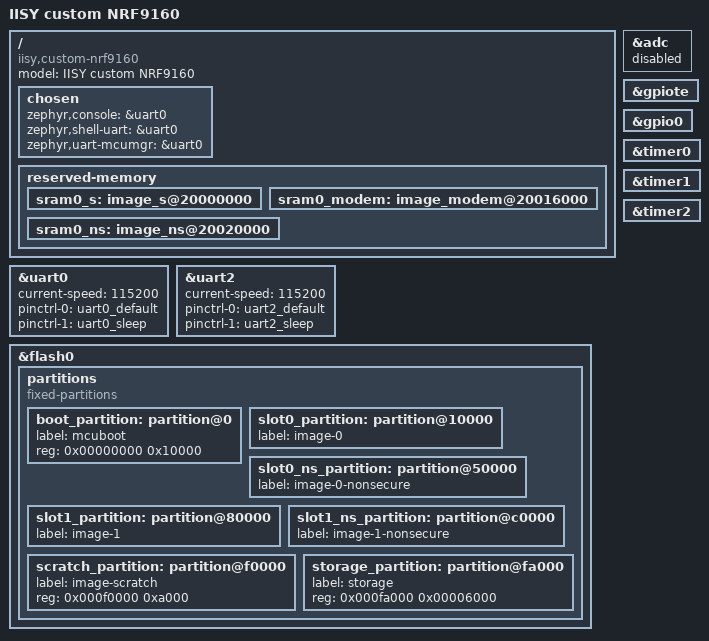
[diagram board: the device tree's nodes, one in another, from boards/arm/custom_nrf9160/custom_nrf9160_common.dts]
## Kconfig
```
#
# Copyright (c) 2019 Nordic Semiconductor
#
# SPDX-License-Identifier: LicenseRef-Nordic-5-Clause
#

source "Kconfig.zephyr"

menu "Nordic Serial LTE Modem"

config SLM_CUSTOMIZED
	bool "Flag for customized functionality"
	help
	  Enable this flag to include customized logic.

config SLM_AT_MODE
	bool "Serial LTE Modem by raw AT mode"
	default y
	select AT_CMD_PARSER

config SLM_AT_MAX_PARAM
	int "Maximum number of parameters in AT command"
	default 42

config SLM_NATIVE_TLS
	bool "Use Zephyr mbedTLS"

#
# external XTAL for UART
#
config SLM_EXTERNAL_XTAL
	bool "Use external XTAL for UARTE"
	default y

#
# Inter-Connect
#
config SLM_UART_HWFC_RUNTIME
	bool "Support of UART HWFC runtime configuration"
	help
		Selected if hw-flow-control is enabled in devicetree
choice
	prompt "UART for interconnect"
	help
		Selects which UART to use for interconnect:
		-  UART 0
		-  UART 2
	config SLM_CONNECT_UART_0
		bool "UART 0"
		select SLM_UART_HWFC_RUNTIME if $(dt_node_has_prop,uart0,hw-flow-control)

	config SLM_CONNECT_UART_2
		bool "UART 2"
		select SLM_UART_HWFC_RUNTIME if $(dt_node_has_prop,uart2,hw-flow-control)
endchoice

choice
	prompt "Termination mode"
	default SLM_CR_LF_TERMINATION
	help
		Sets the command terminator used by the serial terminal.
		Available options are:
		-  CR termination
		-  LF termination
		-  CR+LF termination
	config SLM_CR_TERMINATION
		bool "CR termination"
	config SLM_LF_TERMINATION
		bool "LF termination"
	config SLM_CR_LF_TERMINATION
		bool "CR+LF termination"
endchoice

#
# GPIO wakeup
#
config SLM_START_SLEEP
	bool "Enter sleep on startup"
	help
	  Put nRF9160 into deep sleep mode after startup.

config SLM_WAKEUP_PIN
	int "Wakeup pin"
	default -1
	help
	  Interface GPIO to wake up from sleep or exit idle

config SLM_INDICATE_PIN
	int "Indicate pin"
	default -1
	help
	  Interface GPIO pin used to indicate that data is available or an unexpected reset has occurred

config SLM_INDICATE_TIME
	int "Indication period"
	default 100
	help
	  GPIO active indication time in milliseconds. This setting specify the period length for the pin to be active

#
# Socket
#
config SLM_SOCKET_RX_MAX
	int "Maximum RX buffer size for receiving socket data"
	range 576 708
	default 576
	help
	  Default: NET_IPV4_MTU (576)
	  Maximum: MSS setting in modem (708)

#
# TCP/TLS proxy
#
config SLM_TCP_POLL_TIME
	int "Poll time-out in seconds for TCP connection"
	default 10

config SLM_UDP_POLL_TIME
	int "Poll time-out in seconds for UDP connection"
	default 10

#
# Data mode
#
config SLM_DATAMODE_TERMINATOR
	string "Pattern string to terminate data mode"
	default "+++"
	help
	  Use a pattern to terminate data mode

#
# Configurable services
#
config SLM_SMS
	bool "SMS support in SLM"
	default n
	select SMS
	help
	  Support SMS send/receive in plain text

rsource "src/gnss/Kconfig"
rsource "src/ftp_c/Kconfig"
rsource "src/mqtt_c/Kconfig"
rsource "src/http_c/Kconfig"
rsource "src/twi/Kconfig"
rsource "src/gpio/Kconfig"
rsource "src/dfu/Kconfig"

module = SLM
module-str = serial modem
source "${ZEPHYR_BASE}/subsys/logging/Kconfig.template.log_config"

endmenu
```

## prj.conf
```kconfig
#
# Copyright (c) 2020 Nordic Semiconductor ASA
#
# SPDX-License-Identifier: LicenseRef-Nordic-5-Clause
#
# General config
CONFIG_LOG=y
CONFIG_LOG_DEFAULT_LEVEL=3
CONFIG_STACK_SENTINEL=y
CONFIG_NEWLIB_LIBC=y
CONFIG_NEWLIB_LIBC_FLOAT_PRINTF=y
CONFIG_RING_BUFFER=y

# Segger RTT
CONFIG_USE_SEGGER_RTT=y
CONFIG_RTT_CONSOLE=y
CONFIG_UART_CONSOLE=n
CONFIG_LOG_BACKEND_RTT=y
CONFIG_LOG_BACKEND_UART=n

# Network
CONFIG_NETWORKING=y
CONFIG_NET_SOCKETS=y
CONFIG_NET_NATIVE=n

# Modem library
CONFIG_NRF_MODEM_LIB=y
# Align the max FD entry to NRF_MODEM_MAX_SOCKET_COUNT(8)
CONFIG_POSIX_MAX_FDS=8
# Enable below for modem trace
#CONFIG_NRF_MODEM_LIB_TRACE_ENABLED=y
# Handle modem fault
CONFIG_NRF_MODEM_LIB_ON_FAULT_APPLICATION_SPECIFIC=y

# Use GPIO
CONFIG_GPIO=y
CONFIG_GPIO_NRFX=y

# UART interface
CONFIG_SERIAL=y
CONFIG_UART_ASYNC_API=y
CONFIG_NRFX_TIMER2=y

# Stacks and heaps
CONFIG_MAIN_STACK_SIZE=4096
CONFIG_HEAP_MEM_POOL_SIZE=16384
CONFIG_SYSTEM_WORKQUEUE_STACK_SIZE=4096

# Device power management
CONFIG_PM_DEVICE=y

# FOTA
CONFIG_HTTP_PARSER_URL=y
CONFIG_FOTA_DOWNLOAD=y
CONFIG_FOTA_DOWNLOAD_PROGRESS_EVT=y
CONFIG_DFU_TARGET=y
CONFIG_DOWNLOAD_CLIENT=y
CONFIG_DOWNLOAD_CLIENT_STACK_SIZE=4096
CONFIG_BOOTLOADER_MCUBOOT=y
CONFIG_IMG_MANAGER=y

# FLASH
CONFIG_FLASH=y
CONFIG_FLASH_PAGE_LAYOUT=y
CONFIG_FLASH_MAP=y
CONFIG_MPU_ALLOW_FLASH_WRITE=y
CONFIG_IMG_ERASE_PROGRESSIVELY=y

# Settings
CONFIG_SETTINGS=y
CONFIG_SETTINGS_FCB=y
CONFIG_FCB=y

# nRF Cloud
CONFIG_NRF_CLOUD_MQTT=y
CONFIG_NRF_CLOUD_FOTA=n
CONFIG_NRF_CLOUD_AGPS=y
CONFIG_NRF_CLOUD_AGPS_FILTERED=n
CONFIG_NRF_CLOUD_PGPS=y
CONFIG_NRF_CLOUD_CELL_POS=y
CONFIG_NRF_CLOUD_LOG_LEVEL_INF=y
CONFIG_DATE_TIME=y
CONFIG_MODEM_INFO=y
CONFIG_MODEM_INFO_ADD_DATE_TIME=n
CONFIG_AT_MONITOR=y
CONFIG_MODEM_JWT=y
CONFIG_NRF_CLOUD_CLIENT_ID_SRC_INTERNAL_UUID=y

#
# SLM-specific configurations
#
CONFIG_SLM_CUSTOMIZED=n
CONFIG_SLM_LOG_LEVEL_INF=y
CONFIG_SLM_EXTERNAL_XTAL=n
CONFIG_SLM_START_SLEEP=n

# GNSS
CONFIG_SLM_GNSS=n

# nRF Cloud based location services
CONFIG_SLM_AGPS=n
CONFIG_SLM_PGPS=n
CONFIG_SLM_CELL_POS=n

# Serial DFU support
CONFIG_SLM_NRF52_DFU=n
CONFIG_SLM_NRF52_DFU_LEGACY=n

# FTP Client
CONFIG_SLM_FTPC=n

# MQTT Client
CONFIG_SLM_MQTTC=n

# nRF52 DFU
CONFIG_SLM_NRF52_DFU=n
CONFIG_SLM_NRF52_DFU_LEGACY=n
```

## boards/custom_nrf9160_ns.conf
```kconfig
#
# Copyright (c) 2021 Nordic Semiconductor ASA
#
# SPDX-License-Identifier: LicenseRef-Nordic-5-Clause
#

# Configuration file for custom NRF9160.
# This file is merged with prj.conf in the application folder, and options
# set here will take precedence if they are present in both files.

# Use UART_2
CONFIG_SLM_CONNECT_UART_2=y
CONFIG_UART_2_NRF_HW_ASYNC_TIMER=2
CONFIG_UART_2_NRF_HW_ASYNC=y
```

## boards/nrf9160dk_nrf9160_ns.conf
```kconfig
#
# Copyright (c) 2021 Nordic Semiconductor ASA
#
# SPDX-License-Identifier: LicenseRef-Nordic-5-Clause
#

# Configuration file for nRF9160DK.
# This file is merged with prj.conf in the application folder, and options
# set here will take precedence if they are present in both files.

# Use UART_0 (when working with PC terminal)
# unmask the following config
# CONFIG_SLM_CONNECT_UART_0=y
# CONFIG_UART_0_NRF_HW_ASYNC_TIMER=2
# CONFIG_UART_0_NRF_HW_ASYNC=y
# CONFIG_SLM_WAKEUP_PIN=6
# CONFIG_SLM_INDICATE_PIN=2

# Use UART_2 (when working with external MCU)
# unmask the following config
CONFIG_SLM_CONNECT_UART_2=y
CONFIG_UART_2_NRF_HW_ASYNC_TIMER=2
CONFIG_UART_2_NRF_HW_ASYNC=y
CONFIG_SLM_WAKEUP_PIN=31
CONFIG_SLM_INDICATE_PIN=30
```

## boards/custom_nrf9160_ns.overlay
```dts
/*
 * Copyright (c) 2021 Nordic Semiconductor ASA
 *
 * SPDX-License-Identifier: LicenseRef-Nordic-5-Clause
 */

&uart2 {
	compatible = "nordic,nrf-uarte";
	current-speed = <115200>;
	status = "okay";

	pinctrl-0 = <&uart2_default_alt>;
	pinctrl-1 = <&uart2_sleep_alt>;
	pinctrl-names = "default", "sleep";
};

&pinctrl {
	uart2_default_alt: uart2_default_alt {
		group1 {
			psels = <NRF_PSEL(UART_TX, 0, 29)>,
				<NRF_PSEL(UART_RX, 0, 28)>;
		};
	};

	uart2_sleep_alt: uart2_sleep_alt {
		group1 {
			psels = <NRF_PSEL(UART_TX, 0, 29)>,
				<NRF_PSEL(UART_RX, 0, 28)>;
			low-power-enable;
		};
	};
};
```

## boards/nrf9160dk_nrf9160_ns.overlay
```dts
/*
 * Copyright (c) 2021 Nordic Semiconductor ASA
 *
 * SPDX-License-Identifier: LicenseRef-Nordic-5-Clause
 */

&uart2 {
	compatible = "nordic,nrf-uarte";
	current-speed = <115200>;
	status = "okay";

	pinctrl-0 = <&uart2_default_alt>;
	pinctrl-1 = <&uart2_sleep_alt>;
	pinctrl-names = "default", "sleep";
};

&i2c2 {
	status = "disabled";
};

&pinctrl {
	uart2_default_alt: uart2_default_alt {
		group1 {
			psels = <NRF_PSEL(UART_TX, 0, 11)>,
				<NRF_PSEL(UART_RX, 0, 12)>;
		};
	};

	uart2_sleep_alt: uart2_sleep_alt {
		group1 {
			psels = <NRF_PSEL(UART_TX, 0, 11)>,
				<NRF_PSEL(UART_RX, 0, 12)>;
			low-power-enable;
		};
	};
};
```

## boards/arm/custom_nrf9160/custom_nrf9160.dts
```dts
/*
 * Copyright (c) 2018-2020 Nordic Semiconductor ASA
 *
 * SPDX-License-Identifier: Apache-2.0
 */

/dts-v1/;
#include <nordic/nrf9160_sica.dtsi>
#include "custom_nrf9160_common.dts"

/ {
	chosen {
		zephyr,sram = &sram0_s;
		zephyr,flash = &flash0;
		zephyr,code-partition = &slot0_partition;
		zephyr,sram-secure-partition = &sram0_s;
		zephyr,sram-non-secure-partition = &sram0_ns;
	};
};
```

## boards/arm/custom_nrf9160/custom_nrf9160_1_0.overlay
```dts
/*
 * Copyright (c) 2021 Nordic Semiconductor ASA
 *
 * SPDX-License-Identifier: Apache-2.0
 */

#include "custom_nrf9160_common_1_0.dtsi"
```

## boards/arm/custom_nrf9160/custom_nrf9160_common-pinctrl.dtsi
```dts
/*
 * Copyright (c) 2022 Nordic Semiconductor
 * SPDX-License-Identifier: Apache-2.0
 */

&pinctrl {
	uart0_default: uart0_default {
		group1 {
			psels = <NRF_PSEL(UART_TX, 0, 22)>,
				<NRF_PSEL(UART_RX, 0, 21)>;
		};
	};

	uart0_sleep: uart0_sleep {
		group1 {
			psels = <NRF_PSEL(UART_TX, 0, 22)>,
				<NRF_PSEL(UART_RX, 0, 21)>;
			low-power-enable;
		};
	};

	uart2_default: uart2_default {
		group1 {
			psels = <NRF_PSEL(UART_TX, 0, 29)>,
				<NRF_PSEL(UART_RX, 0, 28)>;
		};
	};

	uart2_sleep: uart2_sleep {
		group1 {
			psels = <NRF_PSEL(UART_TX, 0, 29)>,
				<NRF_PSEL(UART_RX, 0, 28)>;
			low-power-enable;
		};
	};
};
```

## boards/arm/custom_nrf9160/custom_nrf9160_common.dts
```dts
/*
 * Copyright (c) 2018-2020 Nordic Semiconductor ASA
 *
 * SPDX-License-Identifier: Apache-2.0
 */
#include "custom_nrf9160_common-pinctrl.dtsi"

/ {
	model = "IISY custom NRF9160";
	compatible = "iisy,custom-nrf9160";

	chosen {
		zephyr,console = &uart0;
		zephyr,shell-uart = &uart0;
		zephyr,uart-mcumgr = &uart0;
	};
};

&adc {
	status = "disabled";
};

&gpiote {
	status = "okay";
};

&gpio0 {
	status = "okay";
};

&uart0 {
	status = "okay";
	current-speed = <115200>;
	pinctrl-0 = <&uart0_default>;
	pinctrl-1 = <&uart0_sleep>;
	pinctrl-names = "default", "sleep";
};

&uart2 {
	status = "okay";
	current-speed = <115200>;
	pinctrl-0 = <&uart2_default>;
	pinctrl-1 = <&uart2_sleep>;
	pinctrl-names = "default", "sleep";
};

&timer0 {
	status = "okay";
};

&timer1 {
	status = "okay";
};

&timer2 {
	status = "okay";
};

&flash0 {

	partitions {
		compatible = "fixed-partitions";
		#address-cells = <1>;
		#size-cells = <1>;

		boot_partition: partition@0 {
			label = "mcuboot";
			reg = <0x00000000 0x10000>;
		};
		slot0_partition: partition@10000 {
			label = "image-0";
		};
		slot0_ns_partition: partition@50000 {
			label = "image-0-nonsecure";
		};
		slot1_partition: partition@80000 {
			label = "image-1";
		};
		slot1_ns_partition: partition@c0000 {
			label = "image-1-nonsecure";
		};
		scratch_partition: partition@f0000 {
			label = "image-scratch";
			reg = <0x000f0000 0xa000>;
		};
		storage_partition: partition@fa000 {
			label = "storage";
			reg = <0x000fa000 0x00006000>;
		};
	};
};

/ {

	reserved-memory {
		#address-cells = <1>;
		#size-cells = <1>;
		ranges;

		sram0_s: image_s@20000000 {
			/* Secure image memory */
		};

		sram0_modem: image_modem@20016000 {
			/* Modem (shared) memory */
		};

		sram0_ns: image_ns@20020000 {
			/* Non-Secure image memory */
		};
	};
};

/* Include partition configuration file */
#include "custom_nrf9160_partition_conf.dts"
```

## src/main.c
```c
/*
 * Copyright (c) 2019 Nordic Semiconductor ASA
 *
 * SPDX-License-Identifier: LicenseRef-Nordic-5-Clause
 */
#include <zephyr/logging/log.h>
#include <zephyr/logging/log_ctrl.h>

#include <zephyr/kernel.h>
#include <stdio.h>
#include <zephyr/drivers/uart.h>
#include <zephyr/drivers/gpio.h>
#include <string.h>
#include <nrf_modem.h>
#include <hal/nrf_gpio.h>
#include <hal/nrf_power.h>
#include <hal/nrf_regulators.h>
#include <modem/nrf_modem_lib.h>
#include <zephyr/dfu/mcuboot.h>
#include <dfu/dfu_target.h>
#include <zephyr/sys/reboot.h>
#include <zephyr/drivers/clock_control.h>
#include <zephyr/drivers/clock_control/nrf_clock_control.h>
#include "slm_at_host.h"
#include "slm_at_fota.h"

LOG_MODULE_REGISTER(slm, CONFIG_SLM_LOG_LEVEL);

#define SLM_WQ_STACK_SIZE	KB(4)
#define SLM_WQ_PRIORITY		K_LOWEST_APPLICATION_THREAD_PRIO
static K_THREAD_STACK_DEFINE(slm_wq_stack_area, SLM_WQ_STACK_SIZE);

static const struct device *gpio_dev;
static struct gpio_callback gpio_cb;
static struct k_work_delayable indicate_work;

/* global variable used across different files */
struct k_work_q slm_work_q;

/* global variable defined in different files */
extern uint8_t fota_type;
extern uint8_t fota_stage;
extern uint8_t fota_status;
extern int32_t fota_info;

/* global functions defined in different files */
int poweron_uart(void);
int slm_settings_init(void);
int slm_setting_fota_save(void);

/* Forward declarations */
static void indicate_wk(struct k_work *work);

#if defined(CONFIG_NRF_MODEM_LIB_ON_FAULT_APPLICATION_SPECIFIC)
static void on_modem_failure_shutdown(struct k_work *item);
static void on_modem_failure_reinit(struct k_work *item);

K_WORK_DELAYABLE_DEFINE(modem_failure_shutdown_work, on_modem_failure_shutdown);
K_WORK_DELAYABLE_DEFINE(modem_failure_reinit_work, on_modem_failure_reinit);

void nrf_modem_fault_handler(struct nrf_modem_fault_info *fault_info)
{
	char rsp[64];

	sprintf(rsp, "#XMODEM: FAULT,0x%x,0x%x", fault_info->reason, fault_info->program_counter);
	rsp_send(rsp, strlen(rsp));
	/* For now we wait 10 ms to give the trace handler time to process trace data. */
	k_work_reschedule(&modem_failure_shutdown_work, K_MSEC(10));
}

static void on_modem_failure_shutdown(struct k_work *work)
{
	char rsp[32];
	int ret = nrf_modem_lib_shutdown();

	ARG_UNUSED(work);
	sprintf(rsp, "#XMODEM: SHUTDOWN,%d", ret);
	rsp_send(rsp, strlen(rsp));
	k_work_reschedule(&modem_failure_reinit_work, K_MSEC(10));
}

static void on_modem_failure_reinit(struct k_work *work)
{
	char rsp[32];
	int ret = nrf_modem_lib_init(NORMAL_MODE);

	ARG_UNUSED(work);
	sprintf(rsp, "#XMODEM: INIT,%d", ret);
	rsp_send(rsp, strlen(rsp));
}
#endif /* CONFIG_NRF_MODEM_LIB_ON_FAULT_APPLICATION_SPECIFIC */

static int ext_xtal_control(bool xtal_on)
{
	int err = 0;
#if defined(CONFIG_SLM_EXTERNAL_XTAL)
	static struct onoff_manager *clk_mgr;

	if (xtal_on) {
		struct onoff_client cli = {};

		/* request external XTAL for UART */
		clk_mgr = z_nrf_clock_control_get_onoff(CLOCK_CONTROL_NRF_SUBSYS_HF);
		sys_notify_init_spinwait(&cli.notify);
		err = onoff_request(clk_mgr, &cli);
		if (err < 0) {
			LOG_ERR("Clock request failed: %d", err);
			return err;
		}
		while (sys_notify_fetch_result(&cli.notify, &err) < 0) {
			/*empty*/
		}
	} else {
		/* release external XTAL for UART */
		err = onoff_release(clk_mgr);
		if (err < 0) {
			LOG_ERR("Clock release failed: %d", err);
			return err;
		}
	}
#endif

	return err;
}

int indicate_start(void)
{
	int err = 0;

#if (CONFIG_SLM_INDICATE_PIN >= 0)
	if (k_work_delayable_is_pending(&indicate_work)) {
		return 0;
	}
	LOG_DBG("Start indicating");
	gpio_dev = device_get_binding(DT_LABEL(DT_NODELABEL(gpio0)));
	if (gpio_dev == NULL) {
		LOG_ERR("GPIO_0 bind error");
		return -EAGAIN;
	}
	err = gpio_pin_configure(gpio_dev, CONFIG_SLM_INDICATE_PIN, GPIO_OUTPUT);
	if (err) {
		LOG_ERR("GPIO_0 config error: %d", err);
		return -EAGAIN;
	}
	err = gpio_pin_set(gpio_dev, CONFIG_SLM_INDICATE_PIN, 1);
	if (err) {
		LOG_ERR("GPIO_0 set error: %d", err);
	} else {
		k_work_reschedule(&indicate_work, K_MSEC(CONFIG_SLM_INDICATE_TIME));
	}
#endif
	return err;
}

static void indicate_stop(void)
{
#if (CONFIG_SLM_INDICATE_PIN >= 0)
	if (gpio_pin_set(gpio_dev, CONFIG_SLM_INDICATE_PIN, 0) != 0) {
		LOG_WRN("GPIO_0 set error");
	}
	gpio_pin_configure(gpio_dev, CONFIG_SLM_INDICATE_PIN, GPIO_DISCONNECTED);
	LOG_DBG("Stop indicating");
#endif
}

static void gpio_cb_func(const struct device *dev, struct gpio_callback *gpio_cb, uint32_t pins)
{
#if (CONFIG_SLM_WAKEUP_PIN >= 0)
	int err;

	if ((BIT(CONFIG_SLM_WAKEUP_PIN) & pins) == 0) {
		return;
	}
	LOG_INF("Exit idle");
	if (k_work_delayable_is_pending(&indicate_work)) {
		(void)k_work_cancel_delayable(&indicate_work);
		indicate_stop();
	}

	err = ext_xtal_control(true);
	if (err < 0) {
		LOG_WRN("Failed to enable ext XTAL: %d", err);
	}
	err = poweron_uart();
	if (err) {
		LOG_ERR("Failed to power on uart: %d", err);
		return;
	}

	gpio_pin_interrupt_configure(gpio_dev, CONFIG_SLM_WAKEUP_PIN, GPIO_INT_DISABLE);
	gpio_remove_callback(gpio_dev, gpio_cb);
	gpio_pin_configure(gpio_dev, CONFIG_SLM_WAKEUP_PIN, GPIO_DISCONNECTED);
#endif
}

void enter_idle(void)
{
#if (CONFIG_SLM_WAKEUP_PIN >= 0)
	int err;

	gpio_dev = device_get_binding(DT_LABEL(DT_NODELABEL(gpio0)));
	if (gpio_dev == NULL) {
		LOG_ERR("GPIO_0 bind error");
		return;
	}
	err = gpio_pin_configure(gpio_dev, CONFIG_SLM_WAKEUP_PIN, GPIO_INPUT | GPIO_PULL_UP);
	if (err) {
		LOG_ERR("GPIO_0 config error: %d", err);
		return;
	}
	gpio_init_callback(&gpio_cb, gpio_cb_func, BIT(CONFIG_SLM_WAKEUP_PIN));
	err = gpio_add_callback(gpio_dev, &gpio_cb);
	if (err) {
		LOG_ERR("GPIO_0 add callback error: %d", err);
		return;
	}
	err = gpio_pin_interrupt_configure(gpio_dev, CONFIG_SLM_WAKEUP_PIN, GPIO_INT_LEVEL_LOW);
	if (err) {
		LOG_ERR("GPIO_0 enable callback error: %d", err);
		return;
	}

	err = ext_xtal_control(false);
	if (err < 0) {
		LOG_WRN("Failed to disable ext XTAL: %d", err);
	}
#endif
}

void enter_sleep(void)
{
#if (CONFIG_SLM_WAKEUP_PIN >= 0)
	/*
	 * Due to errata 4, Always configure PIN_CNF[n].INPUT before PIN_CNF[n].SENSE.
	 */
	nrf_gpio_cfg_input(CONFIG_SLM_WAKEUP_PIN, NRF_GPIO_PIN_PULLUP);
	nrf_gpio_cfg_sense_set(CONFIG_SLM_WAKEUP_PIN, NRF_GPIO_PIN_SENSE_LOW);

	k_sleep(K_MSEC(100));

	nrf_regulators_system_off(NRF_REGULATORS_NS);
#endif
}

static void handle_nrf_modem_lib_init_ret(void)
{
	int ret = nrf_modem_lib_get_init_ret();

	/* Handle return values relating to modem firmware update */
	switch (ret) {
	case 0:
		return; /* Initialization successful, no action required. */
	case MODEM_DFU_RESULT_OK:
		LOG_INF("MODEM UPDATE OK. Will run new firmware");
		fota_stage = FOTA_STAGE_COMPLETE;
		fota_status = FOTA_STATUS_OK;
		fota_info = 0;
		break;
	case MODEM_DFU_RESULT_UUID_ERROR:
	case MODEM_DFU_RESULT_AUTH_ERROR:
		LOG_ERR("MODEM UPDATE ERROR %d. Will run old firmware", ret);
		fota_status = FOTA_STATUS_ERROR;
		fota_info = ret;
		break;
	case MODEM_DFU_RESULT_HARDWARE_ERROR:
	case MODEM_DFU_RESULT_INTERNAL_ERROR:
		LOG_ERR("MODEM UPDATE FATAL ERROR %d. Modem failure", ret);
		fota_status = FOTA_STATUS_ERROR;
		fota_info = ret;
		break;
	default:
		/* All non-zero return codes other than DFU result codes are
		 * considered irrecoverable and a reboot is needed.
		 */
		LOG_ERR("nRF modem lib initialization failed, error: %d", ret);
		fota_status = FOTA_STATUS_ERROR;
		fota_info = ret;
		break;
	}

	slm_setting_fota_save();
	LOG_WRN("Rebooting...");
	LOG_PANIC();
	sys_reboot(SYS_REBOOT_COLD);
}

void handle_mcuboot_swap_ret(void)
{
	int err;

	/** When a TEST image is swapped to primary partition and booted by MCUBOOT,
	 * the API mcuboot_swap_type() will return BOOT_SWAP_TYPE_REVERT. By this type
	 * MCUBOOT means that the TEST image is booted OK and, if it's not confirmed
	 * next, it'll be swapped back to secondary partition and original application
	 * image will be restored to the primary partition (so-called Revert).
	 */
	int type = mcuboot_swap_type();

	fota_stage = FOTA_STAGE_COMPLETE;
	switch (type) {
	/** Attempt to boot the contents of slot 0. */
	case BOOT_SWAP_TYPE_NONE:
	/** Swap to slot 1. Absent a confirm command, revert back on next boot. */
	case BOOT_SWAP_TYPE_TEST:
	/** Swap to slot 1, and permanently switch to booting its contents. */
	case BOOT_SWAP_TYPE_PERM:
		fota_status = FOTA_STATUS_ERROR;
		fota_info = -EBADF;
		break;
	/** Swap back to alternate slot. A confirm changes this state to NONE. */
	case BOOT_SWAP_TYPE_REVERT:
		err = boot_write_img_confirmed();
		if (err) {
			fota_status = FOTA_STATUS_ERROR;
			fota_info = err;
		} else {
			fota_status = FOTA_STATUS_OK;
			fota_info = 0;
		} break;
		break;
	/** Swap failed because image to be run is not valid */
	case BOOT_SWAP_TYPE_FAIL:
	default:
		break;
	}
}

int start_execute(void)
{
	int err;
	static bool slm_started;

	if (!slm_started) {
		LOG_INF("Serial LTE Modem");
		err = ext_xtal_control(true);
		if (err < 0) {
			LOG_ERR("Failed to enable ext XTAL: %d", err);
			return err;
		}
		err = slm_at_host_init();
		if (err) {
			LOG_ERR("Failed to init at_host: %d", err);
			return err;
		}
		k_work_queue_start(&slm_work_q, slm_wq_stack_area,
				   K_THREAD_STACK_SIZEOF(slm_wq_stack_area),
				   SLM_WQ_PRIORITY, NULL);
		slm_started = true;
	}

	return 0;
}

static void indicate_wk(struct k_work *work)
{
	ARG_UNUSED(work);

	indicate_stop();
	(void)start_execute();
}

int main(void)
{
	uint32_t rr = nrf_power_resetreas_get(NRF_POWER_NS);

	nrf_power_resetreas_clear(NRF_POWER_NS, 0x70017);
	LOG_DBG("RR: 0x%08x", rr);
	k_work_init_delayable(&indicate_work, indicate_wk);

	/* Init and load settings */
	if (slm_settings_init() != 0) {
		LOG_WRN("Failed to init slm settings");
	}
	/* Post-FOTA handling */
	if (fota_stage != FOTA_STAGE_INIT) {
		if (fota_type == DFU_TARGET_IMAGE_TYPE_MODEM_DELTA) {
			handle_nrf_modem_lib_init_ret();
		} else if (fota_type == DFU_TARGET_IMAGE_TYPE_MCUBOOT) {
			handle_mcuboot_swap_ret();
		} else {
			LOG_ERR("Unknown DFU type: %d", fota_type);
			fota_status = FOTA_STATUS_ERROR;
			fota_info = -EAGAIN;
		}
		return start_execute();
	}

#if defined(CONFIG_SLM_START_SLEEP)
	if ((rr & NRF_POWER_RESETREAS_OFF_MASK) ||     /* DETECT signal from GPIO*/
	    (rr & NRF_POWER_RESETREAS_DIF_MASK)) {     /* Entering debug interface mode */
		return start_execute();
	}
	enter_sleep();
	return 0;
#else
#if (CONFIG_SLM_INDICATE_PIN >= 0)
	if ((rr & NRF_POWER_RESETREAS_DOG_MASK) ||     /* watch dog reset */
	    (rr & NRF_POWER_RESETREAS_SREQ_MASK) ||    /* software reset */
	    (rr & NRF_POWER_RESETREAS_LOCKUP_MASK)) {  /* CPU lockup reset */
		if (indicate_start() == 0) {
			return 0;
		}
	}
#endif /* CONFIG_SLM_INDICATE_PIN >= 0 */
	return start_execute();
#endif /* CONFIG_SLM_START_SLEEP */
}
```

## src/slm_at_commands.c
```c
/*
 * Copyright (c) 2021 Nordic Semiconductor ASA
 *
 * SPDX-License-Identifier: LicenseRef-Nordic-5-Clause
 */
#include <zephyr/types.h>
#include <zephyr/sys/util.h>
#include <zephyr/kernel.h>
#include <stdio.h>
#include <ctype.h>
#include <zephyr/logging/log.h>
#include <zephyr/drivers/uart.h>
#include <string.h>
#include <zephyr/init.h>
#include <modem/at_cmd_parser.h>
#include <modem/modem_jwt.h>
#include <zephyr/sys/reboot.h>
#include "ncs_version.h"

#include "slm_util.h"
#include "slm_at_host.h"
#include "slm_at_tcp_proxy.h"
#include "slm_at_udp_proxy.h"
#include "slm_at_socket.h"
#if defined(CONFIG_SLM_NATIVE_TLS)
#include "slm_at_cmng.h"
#endif
#include "slm_at_icmp.h"
#include "slm_at_sms.h"
#include "slm_at_fota.h"
#if defined(CONFIG_SLM_GNSS)
#include "slm_at_gnss.h"
#endif
#if defined(CONFIG_SLM_FTPC)
#include "slm_at_ftp.h"
#endif
#if defined(CONFIG_SLM_MQTTC)
#include "slm_at_mqtt.h"
#endif
#if defined(CONFIG_SLM_HTTPC)
#include "slm_at_httpc.h"
#endif
#if defined(CONFIG_SLM_TWI)
#include "slm_at_twi.h"
#endif
#if defined(CONFIG_SLM_GPIO)
#include "slm_at_gpio.h"
#endif
#if defined(CONFIG_SLM_NRF52_DFU)
#include "slm_at_dfu.h"
#endif

LOG_MODULE_REGISTER(slm_at, CONFIG_SLM_LOG_LEVEL);

/* This delay is necessary for at_host to send response message in low baud rate. */
#define SLM_UART_RESPONSE_DELAY 50

/**@brief Shutdown modes. */
enum shutdown_modes {
	SHUTDOWN_MODE_INVALID,
	SHUTDOWN_MODE_SLEEP,
	SHUTDOWN_MODE_IDLE
};

/**@brief AT command handler type. */
typedef int (*slm_at_handler_t) (enum at_cmd_type);

static struct slm_work_info {
	struct k_work_delayable uart_work;
	struct k_work_delayable sleep_work;
	uint32_t data;
} slm_work;

/* global variable defined in different files */
extern struct at_param_list at_param_list;
extern char rsp_buf[SLM_AT_CMD_RESPONSE_MAX_LEN];
extern uint16_t datamode_time_limit;
extern struct uart_config slm_uart;

/* global functions defined in different files */
void enter_idle(void);
void enter_sleep(void);
int slm_uart_configure(void);
int poweroff_uart(void);
bool verify_datamode_control(uint16_t time_limit, uint16_t *time_limit_min);
extern int slm_setting_uart_save(void);

static void modem_power_off(void)
{
	/*
	 * The LTE modem also needs to be stopped by issuing AT command
	 * through the modem API, before entering System OFF mode.
	 * Once the command is issued, one should wait for the modem
	 * to respond that it actually has stopped as there may be a
	 * delay until modem is disconnected from the network.
	 * Refer to https://infocenter.nordicsemi.com/topic/ps_nrf9160/
	 * pmu.html?cp=2_0_0_4_0_0_1#system_off_mode
	 */
	(void)nrf_modem_at_printf("AT+CFUN=0");
	k_sleep(K_SECONDS(1));
}

/**@brief handle AT#XSLMVER commands
 *  #XSLMVER
 *  AT#XSLMVER? not supported
 *  AT#XSLMVER=? not supported
 */
static int handle_at_slmver(enum at_cmd_type type)
{
	int ret = -EINVAL;

	if (type == AT_CMD_TYPE_SET_COMMAND) {
#if defined(CONFIG_SLM_CUSTOMIZED)
		sprintf(rsp_buf, "\r\n#XSLMVER: %s-CUSTOMIZED\r\n",
			STRINGIFY(NCS_VERSION_STRING));
#else
		sprintf(rsp_buf, "\r\n#XSLMVER: %s\r\n",
			STRINGIFY(NCS_VERSION_STRING));
#endif
		rsp_send(rsp_buf, strlen(rsp_buf));
		ret = 0;
	}

	return ret;
}

static void go_sleep_wk(struct k_work *work)
{
#if (CONFIG_SLM_WAKEUP_PIN >= 0)
	ARG_UNUSED(work);

	if (slm_work.data == SHUTDOWN_MODE_IDLE) {
		if (poweroff_uart() == 0) {
			enter_idle();
		} else {
			LOG_ERR("failed to power off UART");
		}
	} else if (slm_work.data == SHUTDOWN_MODE_SLEEP) {
		slm_at_host_uninit();
		modem_power_off();
		enter_sleep();
	}
#endif
}

/**@brief handle AT#XSLEEP commands
 *  AT#XSLEEP=<shutdown_mode>
 *  AT#XSLEEP? not supported
 *  AT#XSLEEP=?
 */
static int handle_at_sleep(enum at_cmd_type type)
{
#if (CONFIG_SLM_WAKEUP_PIN >= 0)
	int ret = -EINVAL;

	if (type == AT_CMD_TYPE_SET_COMMAND) {
		ret = at_params_unsigned_int_get(&at_param_list, 1, &slm_work.data);
		if (ret) {
			return -EINVAL;
		}
		if (slm_work.data == SHUTDOWN_MODE_SLEEP || slm_work.data == SHUTDOWN_MODE_IDLE) {
			k_work_reschedule(&slm_work.sleep_work, K_MSEC(100));
		} else {
			ret = -EINVAL;
		}
	} else if (type == AT_CMD_TYPE_TEST_COMMAND) {
		sprintf(rsp_buf, "\r\n#XSLEEP: (%d,%d)\r\n", SHUTDOWN_MODE_SLEEP,
			SHUTDOWN_MODE_IDLE);
		rsp_send(rsp_buf, strlen(rsp_buf));
		ret = 0;
	}

	return ret;
#endif /* (CONFIG_SLM_WAKEUP_PIN >= 0) */
}

/**@brief handle AT#XRESET commands
 *  AT#XRESET
 *  AT#XRESET? not supported
 *  AT#XRESET=? not supported
 */
static int handle_at_reset(enum at_cmd_type type)
{
	int ret = -EINVAL;
	char ok_str[] = "\r\nOK\r\n";

	if (type == AT_CMD_TYPE_SET_COMMAND) {
		rsp_send(ok_str, strlen(ok_str));
		k_sleep(K_MSEC(SLM_UART_RESPONSE_DELAY));
		slm_at_host_uninit();
		modem_power_off();
		sys_reboot(SYS_REBOOT_COLD);
	}

	return ret;
}

/**@brief handle AT#XUUID commands
 *  AT#XUUID
 *  AT#XUUID? not supported
 *  AT#XUUID=? not supported
 */
static int handle_at_uuid(enum at_cmd_type type)
{
	int ret;

	if (type != AT_CMD_TYPE_SET_COMMAND) {
		return -EINVAL;
	}

	struct nrf_device_uuid dev = {0};

	ret = modem_jwt_get_uuids(&dev, NULL);
	if (ret) {
		LOG_ERR("Get device UUID error: %d", ret);
	} else {
		sprintf(rsp_buf, "\r\n#XUUID: %s\r\n", dev.str);
		rsp_send(rsp_buf, strlen(rsp_buf));
	}

	return ret;
}

static void set_uart_wk(struct k_work *work)
{
	int err;

	err = slm_uart_configure();
	if (err != 0) {
		LOG_ERR("slm_uart_configure: %d", err);
		return;
	}
	err = slm_setting_uart_save();
	if (err != 0) {
		LOG_ERR("uart_config_set: %d", err);
	}
}

/**@brief handle AT#XSLMUART commands
 *  AT#XSLMUART[=<baud_rate>,<hwfc>]
 *  AT#XSLMUART?
 *  AT#XSLMUART=?
 */
static int handle_at_slmuart(enum at_cmd_type type)
{
	int ret = -EINVAL;

	if (type == AT_CMD_TYPE_SET_COMMAND) {
		uint32_t baudrate;
		uint16_t hwfc;

		ret = at_params_unsigned_int_get(&at_param_list, 1, &baudrate);

		if (ret == 0) {
			switch (baudrate) {
			case 1200:
			case 2400:
			case 4800:
			case 9600:
			case 14400:
			case 19200:
			case 38400:
			case 57600:
			case 115200:
			case 230400:
			case 460800:
			case 921600:
			case 1000000:
				slm_uart.baudrate = baudrate;
				break;
			default:
				LOG_ERR("Invalid uart baud rate provided. %d", baudrate);
				return -EINVAL;
			}
		}
#if defined(CONFIG_SLM_UART_HWFC_RUNTIME)
		ret = at_params_unsigned_short_get(&at_param_list, 2, &hwfc);
		if (ret == 0) {
			if ((hwfc != UART_CFG_FLOW_CTRL_RTS_CTS) &&
				(hwfc != UART_CFG_FLOW_CTRL_NONE)) {
				LOG_ERR("Invalid uart hwfc provided.");
				return -EINVAL;
			}
		}
#else
		hwfc = UART_CFG_FLOW_CTRL_NONE;
#endif
		slm_uart.flow_ctrl = hwfc;

		ret = k_work_reschedule(&slm_work.uart_work, K_MSEC(SLM_UART_RESPONSE_DELAY));
		if (ret > 0) {
			ret = 0;
		}
	}
	if (type == AT_CMD_TYPE_READ_COMMAND) {
		sprintf(rsp_buf, "\r\n#XSLMUART: %d,%d\r\n", slm_uart.baudrate, slm_uart.flow_ctrl);
		rsp_send(rsp_buf, strlen(rsp_buf));
		ret = 0;
	}
	if (type == AT_CMD_TYPE_TEST_COMMAND) {
#if defined(CONFIG_SLM_UART_HWFC_RUNTIME)
		sprintf(rsp_buf, "\r\n#XSLMUART: (1200,2400,4800,9600,14400,19200,38400,57600,"
				 "115200,230400,460800,921600,1000000),(0,1)\r\n");
#else
		sprintf(rsp_buf, "\r\n#XSLMUART: (1200,2400,4800,9600,14400,19200,38400,57600,"
				 "115200,230400,460800,921600,1000000)\r\n");
#endif
		rsp_send(rsp_buf, strlen(rsp_buf));
		ret = 0;
	}
	return ret;
}

/**@brief handle AT#XDATACTRL commands
 *  AT#XDATACTRL=<time_limit>
 *  AT#XDATACTRL?
 *  AT#XDATACTRL=?
 */
static int handle_at_datactrl(enum at_cmd_type cmd_type)
{
	int ret = 0;
	uint16_t time_limit, time_limit_min;

	switch (cmd_type) {
	case AT_CMD_TYPE_SET_COMMAND:
		ret = at_params_unsigned_short_get(&at_param_list, 1, &time_limit);
		if (ret) {
			return ret;
		}
		if (verify_datamode_control(time_limit, NULL)) {
			datamode_time_limit = time_limit;
		} else {
			return -EINVAL;
		}
		break;

	case AT_CMD_TYPE_READ_COMMAND:
		(void)verify_datamode_control(datamode_time_limit, &time_limit_min);
		sprintf(rsp_buf, "\r\n#XDATACTRL: %d,%d\r\n", datamode_time_limit, time_limit_min);
		rsp_send(rsp_buf, strlen(rsp_buf));
		break;

	case AT_CMD_TYPE_TEST_COMMAND:
		sprintf(rsp_buf, "\r\n#XDATACTRL=<time_limit>\r\n");
		rsp_send(rsp_buf, strlen(rsp_buf));
		break;

	default:
		break;
	}

	return ret;
}

/**@brief handle AT#XCLAC commands
 *  AT#XCLAC
 *  AT#XCLAC? not supported
 *  AT#XCLAC=? not supported
 */
int handle_at_clac(enum at_cmd_type cmd_type);

/* TCP proxy commands */
int handle_at_tcp_server(enum at_cmd_type cmd_type);
int handle_at_tcp_client(enum at_cmd_type cmd_type);
int handle_at_tcp_send(enum at_cmd_type cmd_type);
int handle_at_tcp_hangup(enum at_cmd_type cmd_type);

/* UDP proxy commands */
int handle_at_udp_server(enum at_cmd_type cmd_type);
int handle_at_udp_client(enum at_cmd_type cmd_type);
int handle_at_udp_send(enum at_cmd_type cmd_type);

/* Socket-type TCPIP commands */
int handle_at_socket(enum at_cmd_type cmd_type);
int handle_at_secure_socket(enum at_cmd_type cmd_type);
int handle_at_socket_select(enum at_cmd_type cmd_type);
int handle_at_socketopt(enum at_cmd_type cmd_type);
int handle_at_secure_socketopt(enum at_cmd_type cmd_type);
int handle_at_bind(enum at_cmd_type cmd_type);
int handle_at_connect(enum at_cmd_type cmd_type);
int handle_at_listen(enum at_cmd_type cmd_type);
int handle_at_accept(enum at_cmd_type cmd_type);
int handle_at_send(enum at_cmd_type cmd_type);
int handle_at_recv(enum at_cmd_type cmd_type);
int handle_at_sendto(enum at_cmd_type cmd_type);
int handle_at_recvfrom(enum at_cmd_type cmd_type);
int handle_at_poll(enum at_cmd_type cmd_type);
int handle_at_getaddrinfo(enum at_cmd_type cmd_type);

#if defined(CONFIG_SLM_NATIVE_TLS)
int handle_at_xcmng(enum at_cmd_type cmd_type);
#endif

/* ICMP commands */
int handle_at_icmp_ping(enum at_cmd_type cmd_type);

#if defined(CONFIG_SLM_SMS)
/* SMS commands */
int handle_at_sms(enum at_cmd_type cmd_type);
#endif

/* FOTA commands */
int handle_at_fota(enum at_cmd_type cmd_type);

#if defined(CONFIG_SLM_GNSS)
int handle_at_gps(enum at_cmd_type cmd_type);
int handle_at_nrf_cloud(enum at_cmd_type cmd_type);
int handle_at_agps(enum at_cmd_type cmd_type);
int handle_at_pgps(enum at_cmd_type cmd_type);
int handle_at_cellpos(enum at_cmd_type cmd_type);
#endif

#if defined(CONFIG_SLM_FTPC)
int handle_at_ftp(enum at_cmd_type cmd_type);
#endif

#if defined(CONFIG_SLM_MQTTC)
int handle_at_mqtt_connect(enum at_cmd_type cmd_type);
int handle_at_mqtt_publish(enum at_cmd_type cmd_type);
int handle_at_mqtt_subscribe(enum at_cmd_type cmd_type);
int handle_at_mqtt_unsubscribe(enum at_cmd_type cmd_type);
#endif

#if defined(CONFIG_SLM_HTTPC)
int handle_at_httpc_connect(enum at_cmd_type cmd_type);
int handle_at_httpc_request(enum at_cmd_type cmd_type);
#endif

#if defined(CONFIG_SLM_TWI)
int handle_at_twi_list(enum at_cmd_type cmd_type);
int handle_at_twi_write(enum at_cmd_type cmd_type);
int handle_at_twi_read(enum at_cmd_type cmd_type);
int handle_at_twi_write_read(enum at_cmd_type cmd_type);
#endif

#if defined(CONFIG_SLM_GPIO)
int handle_at_gpio_configure(enum at_cmd_type cmd_type);
int handle_at_gpio_operate(enum at_cmd_type cmd_type);
#endif

#if defined(CONFIG_SLM_NRF52_DFU)
int handle_at_dfu_get(enum at_cmd_type cmd_type);
int handle_at_dfu_run(enum at_cmd_type cmd_type);
#endif

static struct slm_at_cmd {
	char *string;
	slm_at_handler_t handler;
} slm_at_cmd_list[] = {
	/* Generic commands */
	{"AT#XSLMVER", handle_at_slmver},
#if (CONFIG_SLM_WAKEUP_PIN >= 0)
	{"AT#XSLEEP", handle_at_sleep},
#endif
	{"AT#XRESET", handle_at_reset},
	{"AT#XUUID", handle_at_uuid},
	{"AT#XCLAC", handle_at_clac},
	{"AT#XSLMUART", handle_at_slmuart},
	{"AT#XDATACTRL", handle_at_datactrl},

	/* TCP proxy commands */
	{"AT#XTCPSVR", handle_at_tcp_server},
	{"AT#XTCPCLI", handle_at_tcp_client},
	{"AT#XTCPSEND", handle_at_tcp_send},
	{"AT#XTCPHANGUP", handle_at_tcp_hangup},

	/* UDP proxy commands */
	{"AT#XUDPSVR", handle_at_udp_server},
	{"AT#XUDPCLI", handle_at_udp_client},
	{"AT#XUDPSEND", handle_at_udp_send},

	/* Socket-type TCPIP commands */
	{"AT#XSOCKET", handle_at_socket},
	{"AT#XSSOCKET", handle_at_secure_socket},
	{"AT#XSOCKETSELECT", handle_at_socket_select},
	{"AT#XSOCKETOPT", handle_at_socketopt},
	{"AT#XSSOCKETOPT", handle_at_secure_socketopt},
	{"AT#XBIND", handle_at_bind},
	{"AT#XCONNECT", handle_at_connect},
	{"AT#XLISTEN", handle_at_listen},
	{"AT#XACCEPT", handle_at_accept},
	{"AT#XSEND", handle_at_send},
	{"AT#XRECV", handle_at_recv},
	{"AT#XSENDTO", handle_at_sendto},
	{"AT#XRECVFROM", handle_at_recvfrom},
	{"AT#XPOLL", handle_at_poll},
	{"AT#XGETADDRINFO", handle_at_getaddrinfo},

#if defined(CONFIG_SLM_NATIVE_TLS)
	{"AT#XCMNG", handle_at_xcmng},
#endif
	/* ICMP commands */
	{"AT#XPING", handle_at_icmp_ping},

#if defined(CONFIG_SLM_SMS)
	/* SMS commands */
	{"AT#XSMS", handle_at_sms},
#endif

	/* FOTA commands */
	{"AT#XFOTA", handle_at_fota},

#if defined(CONFIG_SLM_GNSS)
	/* GNSS commands */
	{"AT#XGPS", handle_at_gps},
	{"AT#XNRFCLOUD", handle_at_nrf_cloud},
#if defined(CONFIG_SLM_AGPS)
	{"AT#XAGPS", handle_at_agps},
#endif
#if defined(CONFIG_SLM_PGPS)
	{"AT#XPGPS", handle_at_pgps},
#endif
#if defined(CONFIG_SLM_CELL_POS)
	{"AT#XCELLPOS", handle_at_cellpos},
#endif
#endif

#if defined(CONFIG_SLM_FTPC)
	/* FTP commands */
	{"AT#XFTP", handle_at_ftp},
#endif

#if defined(CONFIG_SLM_MQTTC)
	{"AT#XMQTTCON", handle_at_mqtt_connect},
	{"AT#XMQTTPUB", handle_at_mqtt_publish},
	{"AT#XMQTTSUB", handle_at_mqtt_subscribe},
	{"AT#XMQTTUNSUB", handle_at_mqtt_unsubscribe},
#endif

#if defined(CONFIG_SLM_HTTPC)
	{"AT#XHTTPCCON", handle_at_httpc_connect},
	{"AT#XHTTPCREQ", handle_at_httpc_request},
#endif

#if defined(CONFIG_SLM_TWI)
	{"AT#XTWILS", handle_at_twi_list},
	{"AT#XTWIW", handle_at_twi_write},
	{"AT#XTWIR", handle_at_twi_read},
	{"AT#XTWIWR", handle_at_twi_write_read},
#endif

#if defined(CONFIG_SLM_GPIO)
	{"AT#XGPIOCFG", handle_at_gpio_configure},
	{"AT#XGPIO", handle_at_gpio_operate},
#endif

#if defined(CONFIG_SLM_NRF52_DFU)
	{"AT#XDFUGET", handle_at_dfu_get},
	{"AT#XDFURUN", handle_at_dfu_run},
#endif
};

int handle_at_clac(enum at_cmd_type cmd_type)
{
	int ret = -EINVAL;

	if (cmd_type == AT_CMD_TYPE_SET_COMMAND) {
		int total = ARRAY_SIZE(slm_at_cmd_list);

		for (int i = 0; i < total; i++) {
			sprintf(rsp_buf, "%s\r\n", slm_at_cmd_list[i].string);
			rsp_send(rsp_buf, strlen(rsp_buf));
		}
		ret = 0;
	}

	return ret;
}

int slm_at_parse(const char *at_cmd)
{
	int ret = -ENOENT;
	int total = ARRAY_SIZE(slm_at_cmd_list);

	for (int i = 0; i < total; i++) {
		if (slm_util_cmd_casecmp(at_cmd, slm_at_cmd_list[i].string)) {
			enum at_cmd_type type = at_parser_cmd_type_get(at_cmd);

			at_params_list_clear(&at_param_list);
			ret = at_parser_params_from_str(at_cmd, NULL, &at_param_list);
			if (ret) {
				LOG_ERR("Failed to parse AT command %d", ret);
				return -EINVAL;
			}
			ret = slm_at_cmd_list[i].handler(type);
			break;
		}
	}

	return ret;
}

int slm_at_init(void)
{
	int err;

	k_work_init_delayable(&slm_work.uart_work, set_uart_wk);
	k_work_init_delayable(&slm_work.sleep_work, go_sleep_wk);

	err = slm_at_tcp_proxy_init();
	if (err) {
		LOG_ERR("TCP Server could not be initialized: %d", err);
		return -EFAULT;
	}
	err = slm_at_udp_proxy_init();
	if (err) {
		LOG_ERR("UDP Server could not be initialized: %d", err);
		return -EFAULT;
	}
	err = slm_at_socket_init();
	if (err) {
		LOG_ERR("TCPIP could not be initialized: %d", err);
		return -EFAULT;
	}
#if defined(CONFIG_SLM_NATIVE_TLS)
	err = slm_at_cmng_init();
	if (err) {
		LOG_ERR("TLS could not be initialized: %d", err);
		return -EFAULT;
	}
#endif
	err = slm_at_icmp_init();
	if (err) {
		LOG_ERR("ICMP could not be initialized: %d", err);
		return -EFAULT;
	}
#if defined(CONFIG_SLM_SMS)
	err = slm_at_sms_init();
	if (err) {
		LOG_ERR("SMS could not be initialized: %d", err);
		return -EFAULT;
	}
#endif
	err = slm_at_fota_init();
	if (err) {
		LOG_ERR("FOTA could not be initialized: %d", err);
		return -EFAULT;
	}
#if defined(CONFIG_SLM_GNSS)
	err = slm_at_gnss_init();
	if (err) {
		LOG_ERR("GPS could not be initialized: %d", err);
		return -EFAULT;
	}
#endif
#if defined(CONFIG_SLM_FTPC)
	err = slm_at_ftp_init();
	if (err) {
		LOG_ERR("FTP could not be initialized: %d", err);
		return -EFAULT;
	}
#endif
#if defined(CONFIG_SLM_MQTTC)
	err = slm_at_mqtt_init();
	if (err) {
		LOG_ERR("MQTT could not be initialized: %d", err);
		return -EFAULT;
	}
#endif
#if defined(CONFIG_SLM_HTTPC)
	err = slm_at_httpc_init();
	if (err) {
		LOG_ERR("HTTP could not be initialized: %d", err);
		return -EFAULT;
	}
#endif
#if defined(CONFIG_SLM_GPIO)
	err = slm_at_gpio_init();
	if (err) {
		LOG_ERR("GPIO could not be initialized: %d", err);
		return -EFAULT;
	}
#endif
#if defined(CONFIG_SLM_TWI)
	err = slm_at_twi_init();
	if (err) {
		LOG_ERR("TWI could not be initialized: %d", err);
		return -EFAULT;
	}
#endif
#if defined(CONFIG_SLM_NRF52_DFU)
	err = slm_at_dfu_init();
	if (err) {
		LOG_ERR("DFU could not be initialized: %d", err);
		return -EFAULT;
	}
#endif

	return err;
}

void slm_at_uninit(void)
{
	int err;

	err = slm_at_tcp_proxy_uninit();
	if (err) {
		LOG_WRN("TCP Server could not be uninitialized: %d", err);
	}
	err = slm_at_udp_proxy_uninit();
	if (err) {
		LOG_WRN("UDP Server could not be uninitialized: %d", err);
	}
	err = slm_at_socket_uninit();
	if (err) {
		LOG_WRN("TCPIP could not be uninitialized: %d", err);
	}
#if defined(CONFIG_SLM_NATIVE_TLS)
	err = slm_at_cmng_uninit();
	if (err) {
		LOG_WRN("TLS could not be uninitialized: %d", err);
	}
#endif
	err = slm_at_icmp_uninit();
	if (err) {
		LOG_WRN("ICMP could not be uninitialized: %d", err);
	}
#if defined(CONFIG_SLM_SMS)
	err = slm_at_sms_uninit();
	if (err) {
		LOG_WRN("SMS could not be uninitialized: %d", err);
	}
#endif
	err = slm_at_fota_uninit();
	if (err) {
		LOG_WRN("FOTA could not be uninitialized: %d", err);
	}
#if defined(CONFIG_SLM_GNSS)
	err = slm_at_gnss_uninit();
	if (err) {
		LOG_WRN("GPS could not be uninitialized: %d", err);
	}
#endif
#if defined(CONFIG_SLM_FTPC)
	err = slm_at_ftp_uninit();
	if (err) {
		LOG_WRN("FTP could not be uninitialized: %d", err);
	}
#endif
#if defined(CONFIG_SLM_MQTTC)
	err = slm_at_mqtt_uninit();
	if (err) {
		LOG_WRN("MQTT could not be uninitialized: %d", err);
	}
#endif
#if defined(CONFIG_SLM_HTTPC)
	err = slm_at_httpc_uninit();
	if (err) {
		LOG_WRN("HTTP could not be uninitialized: %d", err);
	}
#endif
#if defined(CONFIG_SLM_TWI)
	err = slm_at_twi_uninit();
	if (err) {
		LOG_ERR("TWI could not be uninit: %d", err);
	}
#endif
#if defined(CONFIG_SLM_GPIO)
	err = slm_at_gpio_uninit();
	if (err) {
		LOG_ERR("GPIO could not be uninit: %d", err);
	}
#endif
#if defined(CONFIG_SLM_NRF52_DFU)
	err = slm_at_dfu_uninit();
	if (err) {
		LOG_ERR("DFU could not be uninitialized: %d", err);
	}
#endif
}
```
